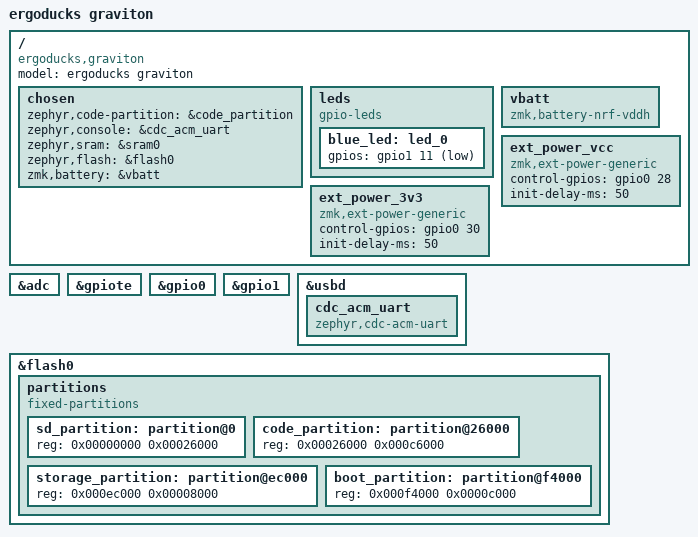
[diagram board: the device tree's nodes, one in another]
/*
 * Copyright (c) 2021 The ZMK Contributors
 *
 * SPDX-License-Identifier: MIT
 */

/dts-v1/;
#include <nordic/nrf52840_qiaa.dtsi>
#include <dt-bindings/zmk/matrix_transform.h>

#include "arduino_pro_micro_pins.dtsi"

/ {
    model = "ergoducks graviton";
    compatible = "ergoducks,graviton";

    chosen {
        zephyr,code-partition = &code_partition;
        zephyr,console = &cdc_acm_uart;
        zephyr,sram = &sram0;
        zephyr,flash = &flash0;
        // Uncomment this if you enabled one of the "vddh" nodes below.
        zmk,battery = &vbatt;
    };

    leds {
        compatible = "gpio-leds";
        blue_led: led_0 {
            gpios = <&gpio1 11 GPIO_ACTIVE_LOW>;
        };
    };

    vbatt: vbatt {
        compatible = "zmk,battery-nrf-vddh";
    };
    
    ext_power_vcc {
        compatible = "zmk,ext-power-generic";
        control-gpios = <&gpio0 28 GPIO_ACTIVE_HIGH>;
        init-delay-ms = <50>;
    };
    ext_power_3v3 {
        compatible = "zmk,ext-power-generic";
        control-gpios = <&gpio0 30 GPIO_ACTIVE_HIGH>;
        init-delay-ms = <50>;
    };
};

&adc {
    status = "okay";
};

&gpiote {
    status = "okay";
};

&gpio0 {
    status = "okay";
};

&gpio1 {
    status = "okay";
};

&usbd {
  status = "okay";
  cdc_acm_uart: cdc_acm_uart {
    compatible = "zephyr,cdc-acm-uart";
  };
};


&flash0 {
    /*
     * For more information, see:
     * http://docs.zephyrproject.org/latest/devices/dts/flash_partitions.html
     */
    partitions {
        compatible = "fixed-partitions";
        #address-cells = <1>;
        #size-cells = <1>;

        sd_partition: partition@0 {
            reg = <0x00000000 0x00026000>;
        };
        code_partition: partition@26000 {
            reg = <0x00026000 0x000c6000>;
        };

        /*
         * The flash starting at 0x000ec000 and ending at
         * 0x000f3fff is reserved for use by the application.
         */

        /*
         * Storage partition will be used by FCB/LittleFS/NVS
         * if enabled.
         */
        storage_partition: partition@ec000 {
            reg = <0x000ec000 0x00008000>;
        };

        boot_partition: partition@f4000 {
            reg = <0x000f4000 0x0000c000>;
        };
    };
};
